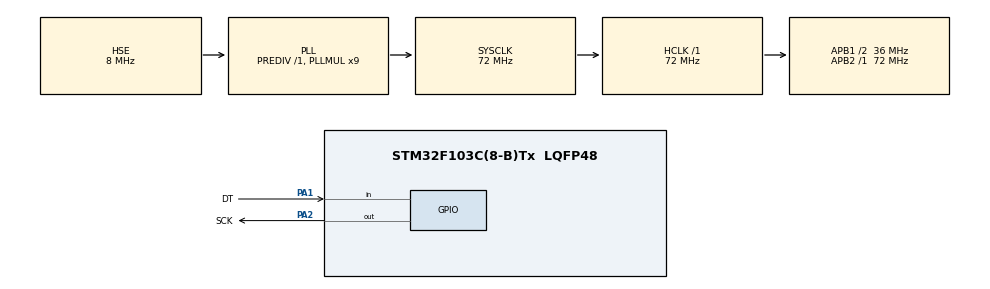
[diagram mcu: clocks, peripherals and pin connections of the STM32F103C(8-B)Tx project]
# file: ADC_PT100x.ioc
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Mcu.Family=STM32F1
RCC.PLLSourceVirtual=RCC_PLLSOURCE_HSE
PD1-OSC_OUT.Mode=HSE-External-Oscillator
PD0-OSC_IN.Signal=RCC_OSC_IN
RCC.APB1CLKDivider=RCC_HCLK_DIV2
RCC.SYSCLKSource=RCC_SYSCLKSOURCE_PLLCLK
ProjectManager.StackSize=0x400
PD1-OSC_OUT.Signal=RCC_OSC_OUT
RCC.ADCPresc=RCC_ADCPCLK2_DIV6
PA13.Signal=SYS_JTMS-SWDIO
TIM1.Prescaler=72-1
ProjectManager.TargetToolchain=STM32CubeIDE
RCC.HCLKFreq_Value=72000000
RCC.APB2TimFreq_Value=72000000
RCC.USBFreq_Value=72000000
PA1.Signal=GPIO_Input
RCC.AHBFreq_Value=72000000
PD0-OSC_IN.Mode=HSE-External-Oscillator
board=custom
RCC.PLLMUL=RCC_PLL_MUL9
RCC.APB2Freq_Value=72000000
PA14.Mode=Serial_Wire
PA1.GPIO_Label=DT
PA13.Mode=Serial_Wire
Mcu.Name=STM32F103C(8-B)Tx
VP_TIM1_VS_ClockSourceINT.Mode=Internal
PA2.Signal=GPIO_Output
RCC.SYSCLKFreq_VALUE=72000000
Mcu.Package=LQFP48
PA2.GPIO_Label=SCK
PA14.Signal=SYS_JTCK-SWCLK
ProjectManager.HeapSize=0x200
NVIC.PriorityGroup=NVIC_PRIORITYGROUP_4
RCC.APB1TimFreq_Value=72000000
RCC.APB1Freq_Value=36000000

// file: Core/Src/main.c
/* USER CODE BEGIN Header */
/**
  ******************************************************************************
  * @file           : main.c
  * @brief          : Main program body
  ******************************************************************************
  * @attention
  *
  * <h2><center>&copy; Copyright (c) 2025 STMicroelectronics.
  * All rights reserved.</center></h2>
  *
  * This software component is licensed by ST under BSD 3-Clause license,
  * the "License"; You may not use this file except in compliance with the
  * License. You may obtain a copy of the License at:
  *                        opensource.org/licenses/BSD-3-Clause
  *
  ******************************************************************************
  */
/* USER CODE END Header */
#include "main.h"

/* USER CODE BEGIN PD */
#define coreClock (72000000) //sacado de un foro falopa (bueno, no tanto ¯\_(ツ)_/¯)
#define SYSTICK_LOAD (SystemCoreClock/1000000U)
#define SYSTICK_DELAY_CALIB (SYSTICK_LOAD >> 1)

#define DELAY_US(us) \
    do { \
         uint32_t start = SysTick->VAL; \
         uint32_t ticks = (us * SYSTICK_LOAD)-SYSTICK_DELAY_CALIB;  \
         while((start - SysTick->VAL) < ticks); \
    } while (0)

/* USER CODE END PD */

TIM_HandleTypeDef htim1;

void SystemClock_Config(void);
static void MX_GPIO_Init(void);
static void MX_TIM1_Init(void);
/* USER CODE BEGIN PFP */

int32_t leer_hx711(uint16_t);
void preparar_hx711(void);
/* USER CODE END PFP */

/* USER CODE BEGIN 0 */
int sensorVal = 0;

void start_timer(TIM_HandleTypeDef* htim)
{
	HAL_TIM_Base_Start(htim);
	__HAL_TIM_SET_COUNTER(htim,0);
}

uint32_t stop_timer(TIM_HandleTypeDef *htim)
{
	uint32_t ret = __HAL_TIM_GET_COUNTER(htim);
	HAL_TIM_Base_Stop(htim);
	return ret;
}

void preparar_hx711(void)
{
	HAL_GPIO_WritePin(SCK_GPIO_Port, SCK_Pin, 0);
}

int32_t leer_hx711(uint16_t comando) //comando son los pulsos extra que setean el canal y la ganancia(1,2,3)
{
	if (comando != 1 && comando != 2 && comando != 3) //small verification to avoid the rage of a Windows's hater
		return -1;

	int32_t reg = 0;
	//uint32_t flag = 0;
	int i=0;

	if(HAL_GPIO_ReadPin(DT_GPIO_Port, DT_Pin)) //cuando leo 0, está listo
		return -1;

	for(i=0; i<(24+comando); i++)	//procedo a enviar los pulsos
	{
		if(i<24)	//ante el OK de data, procedo a enviar pulsos a cambio de bits
			{
				reg<<=1;
				HAL_GPIO_WritePin(SCK_GPIO_Port, SCK_Pin, 1);
				//start_timer(&htim1);				//chequeo de func de delay us
				DELAY_US(1);
				//flag=stop_timer(&htim1);
				//flag++;
				HAL_GPIO_WritePin(SCK_GPIO_Port, SCK_Pin, 0);
				DELAY_US(1);
				if(HAL_GPIO_ReadPin(DT_GPIO_Port, DT_Pin))//coloco el bit correspondiente segun el bit de la trama
					reg|=1;

			}
		if(i>=24) //bits de comando
		{
			HAL_GPIO_WritePin(SCK_GPIO_Port, SCK_Pin, 1);
			DELAY_US(1);
			HAL_GPIO_WritePin(SCK_GPIO_Port, SCK_Pin, 0);
			DELAY_US(1);
		}
		//HAL_GPIO_WritePin(SCK_GPIO_Port, SCK_Pin, 0);
	}
	return reg;
}

/* USER CODE END 0 */

int main(void)
{

  /* MCU Configuration--------------------------------------------------------*/

  /* Reset of all peripherals, Initializes the Flash interface and the Systick. */
  HAL_Init();

  /* USER CODE BEGIN Init */
  preparar_hx711();			//setea clk en 0 para activar la conversion
  /* USER CODE END Init */

  /* Configure the system clock */
  SystemClock_Config();

  /* Initialize all configured peripherals */
  MX_GPIO_Init();
  MX_TIM1_Init();

  /* Infinite loop */
  /* USER CODE BEGIN WHILE */
  while (1)
  {

	  sensorVal  = leer_hx711(2);
	  sensorVal++;
	  HAL_Delay(200);//aplico 100ms de delay, tiempo que tarda en convertir el prox valor

    /* USER CODE END WHILE */

  }
}

void SystemClock_Config(void)
{
  RCC_OscInitTypeDef RCC_OscInitStruct = {0};
  RCC_ClkInitTypeDef RCC_ClkInitStruct = {0};

  /** Initializes the RCC Oscillators according to the specified parameters
  * in the RCC_OscInitTypeDef structure.
  */
  RCC_OscInitStruct.OscillatorType = RCC_OSCILLATORTYPE_HSE;
  RCC_OscInitStruct.HSEState = RCC_HSE_ON;
  RCC_OscInitStruct.HSEPredivValue = RCC_HSE_PREDIV_DIV1;
  RCC_OscInitStruct.HSIState = RCC_HSI_ON;
  RCC_OscInitStruct.PLL.PLLState = RCC_PLL_ON;
  RCC_OscInitStruct.PLL.PLLSource = RCC_PLLSOURCE_HSE;
  RCC_OscInitStruct.PLL.PLLMUL = RCC_PLL_MUL9;
  if (HAL_RCC_OscConfig(&RCC_OscInitStruct) != HAL_OK)
  {
    Error_Handler();
  }
  /** Initializes the CPU, AHB and APB buses clocks
  */
  RCC_ClkInitStruct.ClockType = RCC_CLOCKTYPE_HCLK|RCC_CLOCKTYPE_SYSCLK
                              |RCC_CLOCKTYPE_PCLK1|RCC_CLOCKTYPE_PCLK2;
  RCC_ClkInitStruct.SYSCLKSource = RCC_SYSCLKSOURCE_PLLCLK;
  RCC_ClkInitStruct.AHBCLKDivider = RCC_SYSCLK_DIV1;
  RCC_ClkInitStruct.APB1CLKDivider = RCC_HCLK_DIV2;
  RCC_ClkInitStruct.APB2CLKDivider = RCC_HCLK_DIV1;

  if (HAL_RCC_ClockConfig(&RCC_ClkInitStruct, FLASH_LATENCY_2) != HAL_OK)
  {
    Error_Handler();
  }
}

static void MX_TIM1_Init(void)
{

  TIM_ClockConfigTypeDef sClockSourceConfig = {0};
  TIM_MasterConfigTypeDef sMasterConfig = {0};

  htim1.Instance = TIM1;
  htim1.Init.Prescaler = 72-1;
  htim1.Init.CounterMode = TIM_COUNTERMODE_UP;
  htim1.Init.Period = 65535;
  htim1.Init.ClockDivision = TIM_CLOCKDIVISION_DIV1;
  htim1.Init.RepetitionCounter = 0;
  htim1.Init.AutoReloadPreload = TIM_AUTORELOAD_PRELOAD_DISABLE;
  if (HAL_TIM_Base_Init(&htim1) != HAL_OK)
  {
    Error_Handler();
  }
  sClockSourceConfig.ClockSource = TIM_CLOCKSOURCE_INTERNAL;
  if (HAL_TIM_ConfigClockSource(&htim1, &sClockSourceConfig) != HAL_OK)
  {
    Error_Handler();
  }
  sMasterConfig.MasterOutputTrigger = TIM_TRGO_RESET;
  sMasterConfig.MasterSlaveMode = TIM_MASTERSLAVEMODE_DISABLE;
  if (HAL_TIMEx_MasterConfigSynchronization(&htim1, &sMasterConfig) != HAL_OK)
  {
    Error_Handler();
  }

}

static void MX_GPIO_Init(void)
{
  GPIO_InitTypeDef GPIO_InitStruct = {0};

  /* GPIO Ports Clock Enable */
  __HAL_RCC_GPIOD_CLK_ENABLE();
  __HAL_RCC_GPIOA_CLK_ENABLE();

  /*Configure GPIO pin Output Level */
  HAL_GPIO_WritePin(SCK_GPIO_Port, SCK_Pin, GPIO_PIN_RESET);

  /*Configure GPIO pin : DT_Pin */
  GPIO_InitStruct.Pin = DT_Pin;
  GPIO_InitStruct.Mode = GPIO_MODE_INPUT;
  GPIO_InitStruct.Pull = GPIO_NOPULL;
  HAL_GPIO_Init(DT_GPIO_Port, &GPIO_InitStruct);

  /*Configure GPIO pin : SCK_Pin */
  GPIO_InitStruct.Pin = SCK_Pin;
  GPIO_InitStruct.Mode = GPIO_MODE_OUTPUT_PP;
  GPIO_InitStruct.Pull = GPIO_NOPULL;
  GPIO_InitStruct.Speed = GPIO_SPEED_FREQ_LOW;
  HAL_GPIO_Init(SCK_GPIO_Port, &GPIO_InitStruct);

}

void Error_Handler(void)
{
  __disable_irq();
  while (1)
  {
  }
}

/************************ (C) COPYRIGHT STMicroelectronics *****END OF FILE****/
